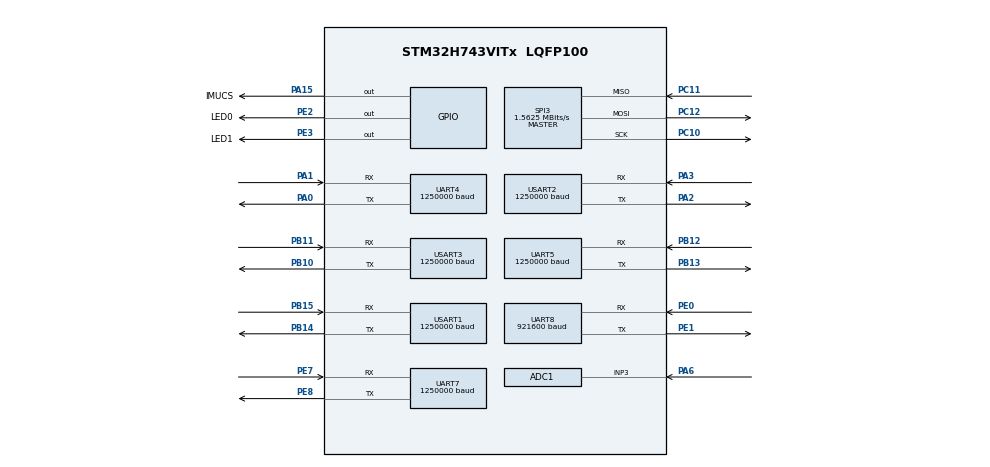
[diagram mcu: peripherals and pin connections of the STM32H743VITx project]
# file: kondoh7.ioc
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ADC1.Channel-0\#ChannelRegularConversion=ADC_CHANNEL_3
ADC1.NbrOfConversionFlag=1
ADC1.OffsetNumber-0\#ChannelRegularConversion=ADC_OFFSET_NONE
ADC1.Rank-0\#ChannelRegularConversion=1
ADC1.SamplingTime-0\#ChannelRegularConversion=ADC_SAMPLETIME_1CYCLE_5
ADC1.master=1
CORTEX_M7.CPU_DCache=Enabled
CORTEX_M7.CPU_ICache=Enabled
Dma.MEMTOMEM.0.Direction=DMA_MEMORY_TO_MEMORY
Dma.MEMTOMEM.0.EventEnable=DISABLE
Dma.MEMTOMEM.0.FIFOMode=DMA_FIFOMODE_ENABLE
Dma.MEMTOMEM.0.FIFOThreshold=DMA_FIFO_THRESHOLD_FULL
Dma.MEMTOMEM.0.Instance=DMA1_Stream0
Dma.MEMTOMEM.0.MemBurst=DMA_MBURST_SINGLE
Dma.MEMTOMEM.0.MemDataAlignment=DMA_MDATAALIGN_BYTE
Dma.MEMTOMEM.0.MemInc=DMA_MINC_ENABLE
Dma.MEMTOMEM.0.Mode=DMA_NORMAL
Dma.MEMTOMEM.0.PeriphBurst=DMA_PBURST_SINGLE
Dma.MEMTOMEM.0.PeriphDataAlignment=DMA_PDATAALIGN_BYTE
Dma.MEMTOMEM.0.PeriphInc=DMA_PINC_ENABLE
Dma.MEMTOMEM.0.Polarity=HAL_DMAMUX_REQ_GEN_RISING
Dma.MEMTOMEM.0.Priority=DMA_PRIORITY_LOW
Dma.MEMTOMEM.0.RequestNumber=1
Dma.MEMTOMEM.0.SyncEnable=DISABLE
Dma.MEMTOMEM.0.SyncPolarity=HAL_DMAMUX_SYNC_NO_EVENT
Dma.MEMTOMEM.0.SyncRequestNumber=1
Dma.Request0=MEMTOMEM
FREERTOS.Queues01=J1vectorqueue,1,pvector,0,Dynamic,NULL,NULL;J2vectorqueue,1,pvector,0,Dynamic,NULL,NULL;J3vectorqueue,1,pvector,0,Dynamic,NULL,NULL;J4vectorqueue,1,pvector,0,Dynamic,NULL,NULL;J5vectorqueue,1,pvector,0,Dynamic,NULL,NULL;J6vectorqueue,1,pvector,0,Dynamic,NULL,NULL
FREERTOS.Tasks01=idleTask,-3,128,StartidleTask,Default,NULL,Dynamic,NULL,NULL;LED1Task,-3,128,StartLED1Task,As weak,NULL,Dynamic,NULL,NULL;LED2Task,-3,128,StartLED2Task,As weak,NULL,Dynamic,NULL,NULL;J1uartport,-2,128,StartJ1uartport,As weak,NULL,Dynamic,NULL,NULL;J2uartport,-3,128,StartJ2uartport,As weak,NULL,Dynamic,NULL,NULL;J3uartport,-3,128,StartJ3uartport,As weak,NULL,Dynamic,NULL,NULL;J4uartport,-3,128,StartJ4uartport,As weak,NULL,Dynamic,NULL,NULL;J5uartport,-3,128,StartJ5uartport,As weak,NULL,Dynamic,NULL,NULL;J6uartport,-3,128,StartJ6uartport,As weak,NULL,Dynamic,NULL,NULL
Mcu.Family=STM32H7
Mcu.Name=STM32H743VITx
Mcu.Package=LQFP100
NVIC.PriorityGroup=NVIC_PRIORITYGROUP_4
NVIC.TIM4_IRQn=true\:0\:0\:false\:false\:true\:false\:false
NVIC.TimeBase=TIM4_IRQn
NVIC.TimeBaseIP=TIM4
NVIC.UART4_IRQn=true\:5\:0\:false\:false\:true\:true\:true
NVIC.UART5_IRQn=true\:5\:0\:false\:false\:true\:true\:true
NVIC.UART7_IRQn=true\:5\:0\:false\:false\:true\:true\:true
NVIC.UART8_IRQn=true\:5\:0\:false\:false\:true\:true\:true
NVIC.USART1_IRQn=true\:5\:0\:false\:false\:true\:true\:true
NVIC.USART2_IRQn=true\:5\:0\:false\:false\:true\:true\:true
NVIC.USART3_IRQn=true\:5\:0\:false\:false\:true\:true\:true
PA0-WKUP.GPIO_ModeDefaultPP=GPIO_MODE_AF_OD
PA0-WKUP.GPIO_PuPd=GPIO_PULLDOWN
PA0-WKUP.GPIO_Speed=GPIO_SPEED_FREQ_HIGH
PA0-WKUP.Mode=Asynchronous
PA0-WKUP.Signal=UART4_TX
PA1.GPIO_ModeDefaultPP=GPIO_MODE_AF_OD
PA1.GPIO_PuPd=GPIO_PULLDOWN
PA1.GPIO_Speed=GPIO_SPEED_FREQ_HIGH
PA1.Mode=Asynchronous
PA1.Signal=UART4_RX
PA13.Mode=Trace_Asynchronous_SW
PA13.Signal=SYS_JTMS-SWDIO
PA14.Mode=Trace_Asynchronous_SW
PA14.Signal=SYS_JTCK-SWCLK
PA15.GPIO_Label=IMUCS
PA15.Signal=GPIO_Output
PA2.GPIO_ModeDefaultPP=GPIO_MODE_AF_OD
PA2.GPIO_PuPd=GPIO_PULLDOWN
PA2.GPIO_Speed=GPIO_SPEED_FREQ_HIGH
PA2.Mode=Asynchronous
PA2.Signal=USART2_TX
PA3.GPIO_ModeDefaultPP=GPIO_MODE_AF_OD
PA3.GPIO_PuPd=GPIO_PULLDOWN
PA3.GPIO_Speed=GPIO_SPEED_FREQ_HIGH
PA3.Mode=Asynchronous
PA3.Signal=USART2_RX
PA6.Signal=ADCx_INP3
PB10.GPIO_ModeDefaultPP=GPIO_MODE_AF_OD
PB10.GPIO_PuPd=GPIO_PULLDOWN
PB10.GPIO_Speed=GPIO_SPEED_FREQ_HIGH
PB10.Mode=Asynchronous
PB10.Signal=USART3_TX
PB11.GPIO_ModeDefaultPP=GPIO_MODE_AF_OD
PB11.GPIO_PuPd=GPIO_PULLDOWN
PB11.GPIO_Speed=GPIO_SPEED_FREQ_HIGH
PB11.Mode=Asynchronous
PB11.Signal=USART3_RX
PB12.GPIO_ModeDefaultPP=GPIO_MODE_AF_OD
PB12.GPIO_PuPd=GPIO_PULLDOWN
PB12.GPIO_Speed=GPIO_SPEED_FREQ_HIGH
PB12.Mode=Asynchronous
PB12.Signal=UART5_RX
PB13.GPIO_ModeDefaultPP=GPIO_MODE_AF_OD
PB13.GPIO_PuPd=GPIO_PULLDOWN
PB13.GPIO_Speed=GPIO_SPEED_FREQ_HIGH
PB13.Mode=Asynchronous
PB13.Signal=UART5_TX
PB14.GPIO_ModeDefaultPP=GPIO_MODE_AF_OD
PB14.GPIO_PuPd=GPIO_PULLDOWN
PB14.GPIO_Speed=GPIO_SPEED_FREQ_HIGH
PB14.Mode=Asynchronous
PB14.Signal=USART1_TX
PB15.GPIO_ModeDefaultPP=GPIO_MODE_AF_OD
PB15.GPIO_PuPd=GPIO_PULLDOWN
PB15.GPIO_Speed=GPIO_SPEED_FREQ_HIGH
PB15.Mode=Asynchronous
PB15.Signal=USART1_RX
PB3.Mode=Trace_Asynchronous_SW
PB3.Signal=SYS_JTDO-SWO
PC10.Mode=Full_Duplex_Master
PC10.Signal=SPI3_SCK
PC11.Mode=Full_Duplex_Master
PC11.Signal=SPI3_MISO
PC12.Mode=Full_Duplex_Master
PC12.Signal=SPI3_MOSI
PE0.GPIO_Speed=GPIO_SPEED_FREQ_VERY_HIGH
PE0.Mode=Asynchronous
PE0.Signal=UART8_RX
PE1.GPIO_Speed=GPIO_SPEED_FREQ_VERY_HIGH
PE1.Mode=Asynchronous
PE1.Signal=UART8_TX
PE2.GPIO_Label=LED0
PE2.GPIO_ModeDefaultOutputPP=GPIO_MODE_OUTPUT_OD
PE2.Signal=GPIO_Output
PE3.GPIO_Label=LED1
PE3.GPIO_ModeDefaultOutputPP=GPIO_MODE_OUTPUT_OD
PE3.Signal=GPIO_Output
PE7.GPIO_ModeDefaultPP=GPIO_MODE_AF_OD
PE7.GPIO_PuPd=GPIO_PULLDOWN
PE7.GPIO_Speed=GPIO_SPEED_FREQ_HIGH
PE7.Mode=Asynchronous
PE7.Signal=UART7_RX
PE8.GPIO_ModeDefaultPP=GPIO_MODE_AF_OD
PE8.GPIO_PuPd=GPIO_PULLDOWN
PE8.GPIO_Speed=GPIO_SPEED_FREQ_HIGH
PE8.Mode=Asynchronous
PE8.Signal=UART7_TX
PH0-OSC_IN.Mode=HSE-External-Oscillator
PH0-OSC_IN.Signal=RCC_OSC_IN
PH1-OSC_OUT.Mode=HSE-External-Oscillator
PH1-OSC_OUT.Signal=RCC_OSC_OUT
ProjectManager.HeapSize=0x200
ProjectManager.StackSize=0x400
ProjectManager.TargetToolchain=TrueSTUDIO
RCC.ADCFreq_Value=152000000
RCC.APB1Freq_Value=100000000
RCC.APB2Freq_Value=100000000
RCC.APB3Freq_Value=100000000
RCC.APB4Freq_Value=100000000
RCC.CortexFreq_Value=400000000
RCC.D1PPRE=RCC_APB3_DIV2
RCC.D2PPRE1=RCC_APB1_DIV2
RCC.D2PPRE2=RCC_APB2_DIV2
RCC.D3PPRE=RCC_APB4_DIV2
RCC.DIVM1=1
RCC.DIVM2=1
RCC.DIVN1=100
RCC.DIVN2=19
RCC.DIVP2=1
RCC.HCLKFreq_Value=200000000
RCC.HPRE=RCC_HCLK_DIV2
RCC.HSE_VALUE=8000000
RCC.PLLSourceVirtual=RCC_PLLSOURCE_HSE
RCC.SYSCLKFreq_VALUE=400000000
RCC.SYSCLKSource=RCC_SYSCLKSOURCE_PLLCLK
RCC.USBFreq_Value=400000000
SH.ADCx_INP3.0=ADC1_INP3,IN3-Single-Ended
SPI3.BaudRatePrescaler=SPI_BAUDRATEPRESCALER_256
SPI3.CalculateBaudRate=1.5625 MBits/s
SPI3.DataSize=SPI_DATASIZE_8BIT
SPI3.Direction=SPI_DIRECTION_2LINES
SPI3.Mode=SPI_MODE_MASTER
SPI3.VirtualType=VM_MASTER
UART4.BaudRate=1250000
UART4.Parity=PARITY_EVEN
UART4.WordLength=WORDLENGTH_9B
UART5.BaudRate=1250000
UART5.Parity=PARITY_EVEN
UART5.WordLength=WORDLENGTH_9B
UART7.BaudRate=1250000
UART7.Parity=PARITY_EVEN
UART7.WordLength=WORDLENGTH_9B
UART8.BaudRate=921600
UART8.DMADisableonRxErrorParam=UART_ADVFEATURE_DMA_ENABLEONRXERROR
UART8.FIFOMode=FIFOMODE_DISABLE
UART8.OverrunDisableParam=UART_ADVFEATURE_OVERRUN_DISABLE
UART8.Prescaler=PRESCALER_DIV1
UART8.RXFIFOThreshold=RXFIFO_THRESHOLD_FULL
UART8.SwapParam=UART_ADVFEATURE_SWAP_ENABLE
UART8.TXFIFOThreshold=TXFIFO_THRESHOLD_EMPTY
UART8.WordLength=WORDLENGTH_8B
USART1.BaudRate=1250000
USART1.Parity=PARITY_EVEN
USART1.VirtualMode-Asynchronous=VM_ASYNC
USART1.WordLength=WORDLENGTH_9B
USART2.BaudRate=1250000
USART2.Parity=PARITY_EVEN
USART2.VirtualMode-Asynchronous=VM_ASYNC
USART2.WordLength=WORDLENGTH_9B
USART3.BaudRate=1250000
USART3.Parity=PARITY_EVEN
USART3.VirtualMode-Asynchronous=VM_ASYNC
USART3.WordLength=WORDLENGTH_9B
VP_FREERTOS_VS_ENABLE.Mode=Enabled
VP_SYS_VS_tim4.Mode=TIM4
board=kondoh7

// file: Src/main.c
/**
  ******************************************************************************
  * @file           : main.c
  * @brief          : Main program body
  ******************************************************************************
  * This notice applies to any and all portions of this file
  * that are not between comment pairs USER CODE BEGIN and
  * USER CODE END. Other portions of this file, whether
  * inserted by the user or by software development tools
  * are owned by their respective copyright owners.
  *
  * Copyright (c) 2018 STMicroelectronics International N.V.
  * All rights reserved.
  *
  * Redistribution and use in source and binary forms, with or without
  * modification, are permitted, provided that the following conditions are met:
  *
  * 1. Redistribution of source code must retain the above copyright notice,
  *    this list of conditions and the following disclaimer.
  * 2. Redistributions in binary form must reproduce the above copyright notice,
  *    this list of conditions and the following disclaimer in the documentation
  *    and/or other materials provided with the distribution.
  * 3. Neither the name of STMicroelectronics nor the names of other
  *    contributors to this software may be used to endorse or promote products
  *    derived from this software without specific written permission.
  * 4. This software, including modifications and/or derivative works of this
  *    software, must execute solely and exclusively on microcontroller or
  *    microprocessor devices manufactured by or for STMicroelectronics.
  * 5. Redistribution and use of this software other than as permitted under
  *    this license is void and will automatically terminate your rights under
  *    this license.
  *
  * THIS SOFTWARE IS PROVIDED BY STMICROELECTRONICS AND CONTRIBUTORS "AS IS"
  * AND ANY EXPRESS, IMPLIED OR STATUTORY WARRANTIES, INCLUDING, BUT NOT
  * LIMITED TO, THE IMPLIED WARRANTIES OF MERCHANTABILITY, FITNESS FOR A
  * PARTICULAR PURPOSE AND NON-INFRINGEMENT OF THIRD PARTY INTELLECTUAL PROPERTY
  * RIGHTS ARE DISCLAIMED TO THE FULLEST EXTENT PERMITTED BY LAW. IN NO EVENT
  * SHALL STMICROELECTRONICS OR CONTRIBUTORS BE LIABLE FOR ANY DIRECT, INDIRECT,
  * INCIDENTAL, SPECIAL, EXEMPLARY, OR CONSEQUENTIAL DAMAGES (INCLUDING, BUT NOT
  * LIMITED TO, PROCUREMENT OF SUBSTITUTE GOODS OR SERVICES; LOSS OF USE, DATA,
  * OR PROFITS; OR BUSINESS INTERRUPTION) HOWEVER CAUSED AND ON ANY THEORY OF
  * LIABILITY, WHETHER IN CONTRACT, STRICT LIABILITY, OR TORT (INCLUDING
  * NEGLIGENCE OR OTHERWISE) ARISING IN ANY WAY OUT OF THE USE OF THIS SOFTWARE,
  * EVEN IF ADVISED OF THE POSSIBILITY OF SUCH DAMAGE.
  *
  ******************************************************************************
  */
#include "main.h"
#include "stm32h7xx_hal.h"
#include "cmsis_os.h"
#include "adc.h"
#include "dma.h"
#include "spi.h"
#include "usart.h"
#include "gpio.h"

/* USER CODE BEGIN PV */
/* Private variables ---------------------------------------------------------*/

/* USER CODE END PV */

void SystemClock_Config(void);
void MX_FREERTOS_Init(void);

/* USER CODE BEGIN PFP */
/* Private function prototypes -----------------------------------------------*/

/* USER CODE END PFP */

/* USER CODE BEGIN 0 */
/* StartLED1Task function */
void StartLED1Task(void const * argument)
{

  /* USER CODE BEGIN StartLED1Task */
  /* Infinite loop */
  for(;;)
  {
	  HAL_GPIO_TogglePin(LED0_GPIO_Port,LED0_Pin);
	  osDelay(200);
  }
  /* USER CODE END StartLED1Task */
}

/* StartLED2Task function */
void StartLED2Task(void const * argument)
{
  /* USER CODE BEGIN StartLED2Task */
  /* Infinite loop */
  for(;;)
  {
    HAL_GPIO_TogglePin(LED1_GPIO_Port,LED1_Pin);
	  osDelay(500);
  }
  /* USER CODE END StartLED2Task */
}
/* USER CODE END 0 */

int main(void)
{

  /* Enable I-Cache-------------------------------------------------------------*/
  SCB_EnableICache();

  /* Enable D-Cache-------------------------------------------------------------*/
  SCB_EnableDCache();

  /* MCU Configuration----------------------------------------------------------*/

  /* Reset of all peripherals, Initializes the Flash interface and the Systick. */
  HAL_Init();

  /* Configure the system clock */
  SystemClock_Config();

  /* Initialize all configured peripherals */
  MX_GPIO_Init();
  MX_DMA_Init();
  MX_ADC1_Init();
  MX_SPI3_Init();
  MX_UART4_Init();
  MX_UART5_Init();
  MX_UART7_Init();
  MX_UART8_Init();
  MX_USART1_UART_Init();
  MX_USART2_UART_Init();
  MX_USART3_UART_Init();

  /* Call init function for freertos objects (in freertos.c) */
  MX_FREERTOS_Init();

  /* Start scheduler */
  osKernelStart();

  /* We should never get here as control is now taken by the scheduler */

  /* Infinite loop */
  while (1)
  {

  }

}

void SystemClock_Config(void)
{

  RCC_OscInitTypeDef RCC_OscInitStruct;
  RCC_ClkInitTypeDef RCC_ClkInitStruct;
  RCC_PeriphCLKInitTypeDef PeriphClkInitStruct;

    /**Supply configuration update enable
    */
  MODIFY_REG(PWR->CR3, PWR_CR3_SCUEN, 0);

    /**Configure the main internal regulator output voltage
    */
  __HAL_PWR_VOLTAGESCALING_CONFIG(PWR_REGULATOR_VOLTAGE_SCALE1);

  while ((PWR->D3CR & (PWR_D3CR_VOSRDY)) != PWR_D3CR_VOSRDY)
  {

  }
    /**Macro to configure the PLL clock source
    */
  __HAL_RCC_PLL_PLLSOURCE_CONFIG(RCC_PLLSOURCE_HSE);

    /**Initializes the CPU, AHB and APB busses clocks
    */
  RCC_OscInitStruct.OscillatorType = RCC_OSCILLATORTYPE_HSE;
  RCC_OscInitStruct.HSEState = RCC_HSE_ON;
  RCC_OscInitStruct.PLL.PLLState = RCC_PLL_ON;
  RCC_OscInitStruct.PLL.PLLSource = RCC_PLLSOURCE_HSE;
  RCC_OscInitStruct.PLL.PLLM = 1;
  RCC_OscInitStruct.PLL.PLLN = 100;
  RCC_OscInitStruct.PLL.PLLP = 2;
  RCC_OscInitStruct.PLL.PLLQ = 2;
  RCC_OscInitStruct.PLL.PLLR = 2;
  RCC_OscInitStruct.PLL.PLLRGE = RCC_PLL1VCIRANGE_3;
  RCC_OscInitStruct.PLL.PLLVCOSEL = RCC_PLL1VCOWIDE;
  RCC_OscInitStruct.PLL.PLLFRACN = 0;
  if (HAL_RCC_OscConfig(&RCC_OscInitStruct) != HAL_OK)
  {
    _Error_Handler(__FILE__, __LINE__);
  }

    /**Initializes the CPU, AHB and APB busses clocks
    */
  RCC_ClkInitStruct.ClockType = RCC_CLOCKTYPE_HCLK|RCC_CLOCKTYPE_SYSCLK
                              |RCC_CLOCKTYPE_PCLK1|RCC_CLOCKTYPE_PCLK2
                              |RCC_CLOCKTYPE_D3PCLK1|RCC_CLOCKTYPE_D1PCLK1;
  RCC_ClkInitStruct.SYSCLKSource = RCC_SYSCLKSOURCE_PLLCLK;
  RCC_ClkInitStruct.SYSCLKDivider = RCC_SYSCLK_DIV1;
  RCC_ClkInitStruct.AHBCLKDivider = RCC_HCLK_DIV2;
  RCC_ClkInitStruct.APB3CLKDivider = RCC_APB3_DIV2;
  RCC_ClkInitStruct.APB1CLKDivider = RCC_APB1_DIV2;
  RCC_ClkInitStruct.APB2CLKDivider = RCC_APB2_DIV2;
  RCC_ClkInitStruct.APB4CLKDivider = RCC_APB4_DIV2;

  if (HAL_RCC_ClockConfig(&RCC_ClkInitStruct, FLASH_LATENCY_2) != HAL_OK)
  {
    _Error_Handler(__FILE__, __LINE__);
  }

  PeriphClkInitStruct.PeriphClockSelection = RCC_PERIPHCLK_USART3|RCC_PERIPHCLK_USART2
                              |RCC_PERIPHCLK_UART4|RCC_PERIPHCLK_UART7
                              |RCC_PERIPHCLK_USART1|RCC_PERIPHCLK_UART8
                              |RCC_PERIPHCLK_UART5|RCC_PERIPHCLK_SPI3
                              |RCC_PERIPHCLK_ADC;
  PeriphClkInitStruct.PLL2.PLL2M = 1;
  PeriphClkInitStruct.PLL2.PLL2N = 19;
  PeriphClkInitStruct.PLL2.PLL2P = 1;
  PeriphClkInitStruct.PLL2.PLL2Q = 2;
  PeriphClkInitStruct.PLL2.PLL2R = 2;
  PeriphClkInitStruct.PLL2.PLL2RGE = RCC_PLL2VCIRANGE_3;
  PeriphClkInitStruct.PLL2.PLL2VCOSEL = RCC_PLL2VCOMEDIUM;
  PeriphClkInitStruct.PLL2.PLL2FRACN = 0;
  PeriphClkInitStruct.Spi123ClockSelection = RCC_SPI123CLKSOURCE_PLL;
  PeriphClkInitStruct.Usart234578ClockSelection = RCC_USART234578CLKSOURCE_D2PCLK1;
  PeriphClkInitStruct.Usart16ClockSelection = RCC_USART16CLKSOURCE_D2PCLK2;
  PeriphClkInitStruct.AdcClockSelection = RCC_ADCCLKSOURCE_PLL2;
  if (HAL_RCCEx_PeriphCLKConfig(&PeriphClkInitStruct) != HAL_OK)
  {
    _Error_Handler(__FILE__, __LINE__);
  }

    /**Configure the Systick interrupt time
    */
  HAL_SYSTICK_Config(SystemCoreClock/1000);

    /**Configure the Systick
    */
  HAL_SYSTICK_CLKSourceConfig(SYSTICK_CLKSOURCE_HCLK);

  /* SysTick_IRQn interrupt configuration */
  HAL_NVIC_SetPriority(SysTick_IRQn, 15, 0);
}

void HAL_TIM_PeriodElapsedCallback(TIM_HandleTypeDef *htim)
{
  if (htim->Instance == TIM4) {
    HAL_IncTick();
  }
}

void _Error_Handler(char *file, int line)
{
  while(1)
  {
  }
}

/************************ (C) COPYRIGHT STMicroelectronics *****END OF FILE****/

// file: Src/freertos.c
/**
  ******************************************************************************
  * File Name          : freertos.c
  * Description        : Code for freertos applications
  ******************************************************************************
  * This notice applies to any and all portions of this file
  * that are not between comment pairs USER CODE BEGIN and
  * USER CODE END. Other portions of this file, whether
  * inserted by the user or by software development tools
  * are owned by their respective copyright owners.
  *
  * Copyright (c) 2018 STMicroelectronics International N.V.
  * All rights reserved.
  *
  * Redistribution and use in source and binary forms, with or without
  * modification, are permitted, provided that the following conditions are met:
  *
  * 1. Redistribution of source code must retain the above copyright notice,
  *    this list of conditions and the following disclaimer.
  * 2. Redistributions in binary form must reproduce the above copyright notice,
  *    this list of conditions and the following disclaimer in the documentation
  *    and/or other materials provided with the distribution.
  * 3. Neither the name of STMicroelectronics nor the names of other
  *    contributors to this software may be used to endorse or promote products
  *    derived from this software without specific written permission.
  * 4. This software, including modifications and/or derivative works of this
  *    software, must execute solely and exclusively on microcontroller or
  *    microprocessor devices manufactured by or for STMicroelectronics.
  * 5. Redistribution and use of this software other than as permitted under
  *    this license is void and will automatically terminate your rights under
  *    this license.
  *
  * THIS SOFTWARE IS PROVIDED BY STMICROELECTRONICS AND CONTRIBUTORS "AS IS"
  * AND ANY EXPRESS, IMPLIED OR STATUTORY WARRANTIES, INCLUDING, BUT NOT
  * LIMITED TO, THE IMPLIED WARRANTIES OF MERCHANTABILITY, FITNESS FOR A
  * PARTICULAR PURPOSE AND NON-INFRINGEMENT OF THIRD PARTY INTELLECTUAL PROPERTY
  * RIGHTS ARE DISCLAIMED TO THE FULLEST EXTENT PERMITTED BY LAW. IN NO EVENT
  * SHALL STMICROELECTRONICS OR CONTRIBUTORS BE LIABLE FOR ANY DIRECT, INDIRECT,
  * INCIDENTAL, SPECIAL, EXEMPLARY, OR CONSEQUENTIAL DAMAGES (INCLUDING, BUT NOT
  * LIMITED TO, PROCUREMENT OF SUBSTITUTE GOODS OR SERVICES; LOSS OF USE, DATA,
  * OR PROFITS; OR BUSINESS INTERRUPTION) HOWEVER CAUSED AND ON ANY THEORY OF
  * LIABILITY, WHETHER IN CONTRACT, STRICT LIABILITY, OR TORT (INCLUDING
  * NEGLIGENCE OR OTHERWISE) ARISING IN ANY WAY OUT OF THE USE OF THIS SOFTWARE,
  * EVEN IF ADVISED OF THE POSSIBILITY OF SUCH DAMAGE.
  *
  ******************************************************************************
  */

#include "FreeRTOS.h"
#include "task.h"
#include "cmsis_os.h"

/* USER CODE BEGIN Includes */
#include "main.h"
/* USER CODE END Includes */

osThreadId idleTaskHandle;
osThreadId LED1TaskHandle;
osThreadId LED2TaskHandle;
osThreadId J1uartportHandle;
osThreadId J2uartportHandle;
osThreadId J3uartportHandle;
osThreadId J4uartportHandle;
osThreadId J5uartportHandle;
osThreadId J6uartportHandle;
osMessageQId J1vectorqueueHandle;
osMessageQId J2vectorqueueHandle;
osMessageQId J3vectorqueueHandle;
osMessageQId J4vectorqueueHandle;
osMessageQId J5vectorqueueHandle;
osMessageQId J6vectorqueueHandle;

void StartidleTask(void const * argument);
void StartLED1Task(void const * argument);
void StartLED2Task(void const * argument);
void StartJ1uartport(void const * argument);
void StartJ2uartport(void const * argument);
void StartJ3uartport(void const * argument);
void StartJ4uartport(void const * argument);
void StartJ5uartport(void const * argument);
void StartJ6uartport(void const * argument);

void MX_FREERTOS_Init(void); /* (MISRA C 2004 rule 8.1) */

/* Hook prototypes */

/* Init FreeRTOS */

void MX_FREERTOS_Init(void) {

  /* Create the thread(s) */
  /* definition and creation of idleTask */
  osThreadDef(idleTask, StartidleTask, osPriorityIdle, 0, 128);
  idleTaskHandle = osThreadCreate(osThread(idleTask), NULL);

  /* definition and creation of LED1Task */
  osThreadDef(LED1Task, StartLED1Task, osPriorityIdle, 0, 128);
  LED1TaskHandle = osThreadCreate(osThread(LED1Task), NULL);

  /* definition and creation of LED2Task */
  //osThreadDef(LED2Task, StartLED2Task, osPriorityIdle, 0, 128);
  //LED2TaskHandle = osThreadCreate(osThread(LED2Task), NULL);

  /* definition and creation of J1uartport */
  osThreadDef(J1uartport, StartJ1uartport, osPriorityLow, 0, 128);
  J1uartportHandle = osThreadCreate(osThread(J1uartport), NULL);

  /* definition and creation of J2uartport */
  //osThreadDef(J2uartport, StartJ2uartport, osPriorityIdle, 0, 128);
  //J2uartportHandle = osThreadCreate(osThread(J2uartport), NULL);

  /* definition and creation of J3uartport */
  //osThreadDef(J3uartport, StartJ3uartport, osPriorityIdle, 0, 128);
  //J3uartportHandle = osThreadCreate(osThread(J3uartport), NULL);

  /* definition and creation of J4uartport */
  //osThreadDef(J4uartport, StartJ4uartport, osPriorityIdle, 0, 128);
  //J4uartportHandle = osThreadCreate(osThread(J4uartport), NULL);

  /* definition and creation of J5uartport */
  //osThreadDef(J5uartport, StartJ5uartport, osPriorityIdle, 0, 128);
  //J5uartportHandle = osThreadCreate(osThread(J5uartport), NULL);

  /* definition and creation of J6uartport */
  //osThreadDef(J6uartport, StartJ6uartport, osPriorityIdle, 0, 128);
  //J6uartportHandle = osThreadCreate(osThread(J6uartport), NULL);

  /* Create the queue(s) */
  /* definition and creation of J1vectorqueue */
  osMessageQDef(J1vectorqueue, 1, pvector);
  J1vectorqueueHandle = osMessageCreate(osMessageQ(J1vectorqueue), NULL);

  /* definition and creation of J2vectorqueue */
  //osMessageQDef(J2vectorqueue, 1, pvector);
  //J2vectorqueueHandle = osMessageCreate(osMessageQ(J2vectorqueue), NULL);

  /* definition and creation of J3vectorqueue */
  //osMessageQDef(J3vectorqueue, 1, pvector);
  //J3vectorqueueHandle = osMessageCreate(osMessageQ(J3vectorqueue), NULL);

  /* definition and creation of J4vectorqueue */
  //osMessageQDef(J4vectorqueue, 1, pvector);
  //J4vectorqueueHandle = osMessageCreate(osMessageQ(J4vectorqueue), NULL);

  /* definition and creation of J5vectorqueue */
  //osMessageQDef(J5vectorqueue, 1, pvector);
  //J5vectorqueueHandle = osMessageCreate(osMessageQ(J5vectorqueue), NULL);

  /* definition and creation of J6vectorqueue */
  //osMessageQDef(J6vectorqueue, 1, pvector);
  //J6vectorqueueHandle = osMessageCreate(osMessageQ(J6vectorqueue), NULL);

}

/* StartidleTask function */
void StartidleTask(void const * argument)
{

  for(;;)
  {
    osDelay(1);
  }
}

/* StartLED1Task function */
__weak void StartLED1Task(void const * argument)
{
  for(;;)
  {
    osDelay(1);
  }
}

/* StartLED2Task function */
__weak void StartLED2Task(void const * argument)
{
  for(;;)
  {
    osDelay(1);
  }
}

/* StartJ1uartport function */
__weak void StartJ1uartport(void const * argument)
{
  for(;;)
  {
    osDelay(1);
  }
}

/* StartJ2uartport function */
__weak void StartJ2uartport(void const * argument)
{
  for(;;)
  {
    osDelay(1);
  }
}

/* StartJ3uartport function */
__weak void StartJ3uartport(void const * argument)
{
  for(;;)
  {
    osDelay(1);
  }
}

/* StartJ4uartport function */
__weak void StartJ4uartport(void const * argument)
{
  for(;;)
  {
    osDelay(1);
  }
}

/* StartJ5uartport function */
__weak void StartJ5uartport(void const * argument)
{
  for(;;)
  {
    osDelay(1);
  }
}

/* StartJ6uartport function */
__weak void StartJ6uartport(void const * argument)
{
  for(;;)
  {
    osDelay(1);
  }
}

/************************ (C) COPYRIGHT STMicroelectronics *****END OF FILE****/
